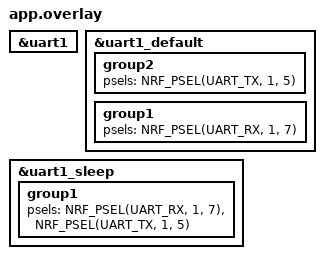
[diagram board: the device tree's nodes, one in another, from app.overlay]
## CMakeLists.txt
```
#
# Copyright (c) 2018 Nordic Semiconductor
#
# SPDX-License-Identifier: LicenseRef-Nordic-5-Clause
#
cmake_minimum_required(VERSION 3.20.0)

find_package(Zephyr REQUIRED HINTS $ENV{ZEPHYR_BASE})
project(ble_gateway)

# NORDIC SDK APP START
target_sources(app PRIVATE
  src/main.c
)
# NORDIC SDK APP END

zephyr_library_include_directories(${CMAKE_CURRENT_SOURCE_DIR})
```

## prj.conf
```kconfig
#
# Copyright (c) 2018 Nordic Semiconductor
#
# SPDX-License-Identifier: LicenseRef-Nordic-5-Clause
#

# Enable the UART driver
CONFIG_UART_ASYNC_API=y
CONFIG_SERIAL=y
CONFIG_CONSOLE=y
CONFIG_UART_CONSOLE=y

# Enable the BLE stack with GATT Client configuration
CONFIG_BT=y
CONFIG_BT_CENTRAL=y
CONFIG_BT_SMP=y
CONFIG_BT_GATT_CLIENT=y

# Enable the BLE modules from NCS
CONFIG_BT_NUS_CLIENT=y
CONFIG_BT_SCAN=y
CONFIG_BT_SCAN_FILTER_ENABLE=y
CONFIG_BT_SCAN_UUID_CNT=1
CONFIG_BT_GATT_DM=y
CONFIG_HEAP_MEM_POOL_SIZE=2048

# This example requires more stack
CONFIG_SYSTEM_WORKQUEUE_STACK_SIZE=2048
CONFIG_MAIN_STACK_SIZE=1536

# Enable bonding
CONFIG_BT_SETTINGS=y
CONFIG_FLASH=y
CONFIG_FLASH_PAGE_LAYOUT=y
CONFIG_FLASH_MAP=y
CONFIG_NVS=y
CONFIG_SETTINGS=y

# Config logger
CONFIG_LOG=y
CONFIG_USE_SEGGER_RTT=y
CONFIG_LOG_BACKEND_RTT=y
CONFIG_LOG_BACKEND_UART=n
CONFIG_LOG_PRINTK=n

CONFIG_ASSERT=y
```

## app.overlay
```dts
&uart1{
    status = "okay";
};
&uart1_default {
    group2 {
        psels = <NRF_PSEL(UART_TX, 1, 5)>;
    };

    group1 {
        psels = <NRF_PSEL(UART_RX, 1, 7)>;
    };
};

&uart1_sleep {
    group1 {
        psels = <NRF_PSEL(UART_RX, 1, 7)>, <NRF_PSEL(UART_TX, 1, 5)>;
    };
};
```

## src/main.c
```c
/*
 * Copyright (c) 2018 Nordic Semiconductor ASA
 *
 * SPDX-License-Identifier: LicenseRef-Nordic-5-Clause
 */

/** @file
 *  @brief Nordic UART Service Client sample
 */

#include <errno.h>
#include <zephyr/kernel.h>
#include <zephyr/device.h>
#include <zephyr/devicetree.h>
#include <zephyr/sys/byteorder.h>
#include <zephyr/sys/printk.h>

#include <zephyr/bluetooth/bluetooth.h>
#include <zephyr/bluetooth/hci.h>
#include <zephyr/bluetooth/conn.h>
#include <zephyr/bluetooth/uuid.h>
#include <zephyr/bluetooth/gatt.h>

#include <bluetooth/services/nus.h>
#include <bluetooth/services/nus_client.h>
#include <bluetooth/gatt_dm.h>
#include <bluetooth/scan.h>

#include <zephyr/settings/settings.h>

#include <zephyr/drivers/uart.h>

#include <zephyr/logging/log.h>

#include "gatt_chars.h"

#define LOG_MODULE_NAME central_uart
LOG_MODULE_REGISTER(LOG_MODULE_NAME);

/* UART payload buffer element size. */
#define UART_BUF_SIZE 20

#define KEY_PASSKEY_ACCEPT DK_BTN1_MSK
#define KEY_PASSKEY_REJECT DK_BTN2_MSK

#define NUS_WRITE_TIMEOUT K_MSEC(150)
#define UART_WAIT_FOR_BUF_DELAY K_MSEC(50)
#define UART_RX_TIMEOUT 50000 /* Wait for RX complete event time in microseconds. 500ms = 50000 */

static const struct device *uart = DEVICE_DT_GET(DT_NODELABEL(uart1));
static struct k_work_delayable uart_work;

K_SEM_DEFINE(nus_write_sem, 0, 1);

struct uart_data_t {
	void *fifo_reserved;
	uint8_t  data[UART_BUF_SIZE];
	uint16_t len;
};

static K_FIFO_DEFINE(fifo_uart_tx_data);
static K_FIFO_DEFINE(fifo_uart_rx_data);

struct bt_bot_client {

        /** Connection object. */
	struct bt_conn *conn;

        /** Internal state. */
	int voltage;
	int rpm;
	uint8_t last_move;

        /** GATT subscribe parameters for BOT voltage & RPM Characteristic. */
	struct bt_gatt_subscribe_params volt_notif_params;
	struct bt_gatt_subscribe_params rpm_notif_params;

        /** GATT write parameters for BOT Move & RPM Characteristic. */
	struct bt_gatt_write_params move_write_params;
	struct bt_gatt_write_params rpm_write_params;
};

static struct bt_conn *default_conn;
static struct bt_bot_client nus_client;

static void ble_data_sent(struct bt_bot_client *nus, uint8_t err,
					const uint8_t *const data, uint16_t len)
{
	ARG_UNUSED(nus);

	k_sem_give(&nus_write_sem);

	if (err) {
		printk("ATT error code: 0x%02X", err);
	}
}

static uint8_t ble_data_received(struct bt_bot_client *nus,
						const uint8_t *data, uint16_t len)
{
	ARG_UNUSED(nus);

	int err;

	for (uint16_t pos = 0; pos != len;) {
		struct uart_data_t *tx = k_malloc(sizeof(*tx));

		if (!tx) {
			printk("Not able to allocate UART send data buffer");
			return BT_GATT_ITER_CONTINUE;
		}

		/* Keep the last byte of TX buffer for potential LF char. */
		size_t tx_data_size = sizeof(tx->data) - 1;

		if ((len - pos) > tx_data_size) {
			tx->len = tx_data_size;
		} else {
			tx->len = (len - pos);
		}

		memcpy(tx->data, &data[pos], tx->len);

		pos += tx->len;

		/* Append the LF character when the CR character triggered
		 * transmission from the peer.
		 */
		if ((pos == len) && (data[len - 1] == '\r')) {
			tx->data[tx->len] = '\n';
			tx->len++;
		}

		err = uart_tx(uart, tx->data, tx->len, SYS_FOREVER_MS);
		if (err) {
			k_fifo_put(&fifo_uart_tx_data, tx);
		}
	}

	return BT_GATT_ITER_CONTINUE;
}

static void uart_cb(const struct device *dev, struct uart_event *evt, void *user_data)
{
	ARG_UNUSED(dev);

	static size_t aborted_len;
	struct uart_data_t *buf;
	static uint8_t *aborted_buf;
	static bool disable_req;
	switch (evt->type) {
	case UART_TX_DONE:
		LOG_DBG("UART_TX_DONE");
		if ((evt->data.tx.len == 0) ||
		    (!evt->data.tx.buf)) {
			printk("TX");
			return;
		}

		if (aborted_buf) {
			buf = CONTAINER_OF(aborted_buf, struct uart_data_t,
					   data[0]);
			aborted_buf = NULL;
			aborted_len = 0;
		} else {
			buf = CONTAINER_OF(evt->data.tx.buf,
					   struct uart_data_t,
					   data[0]);
		}

		k_free(buf);

		buf = k_fifo_get(&fifo_uart_tx_data, K_NO_WAIT);
		if (!buf) {
			return;
		}

		if (uart_tx(uart, buf->data, buf->len, SYS_FOREVER_MS)) {
			printk("Failed to send data over UART");
		}

		break;

	case UART_RX_RDY:
		LOG_DBG("UART_RX_RDY");
		buf = CONTAINER_OF(evt->data.rx.buf, struct uart_data_t, data[0]);
		buf->len += evt->data.rx.len;
		if (disable_req) {
			printk("disabled rx true");
			return;
		}
		if ((evt->data.rx.buf[buf->len - 1] == '\n') ||
		    (evt->data.rx.buf[buf->len - 1] == '\r')) {
			disable_req = true;
			uart_rx_disable(uart);
		}

		break;

	case UART_RX_DISABLED:
		LOG_DBG("UART_RX_DISABLED");
		disable_req = false;
		buf = k_malloc(sizeof(*buf));
		if (buf) {
			buf->len = 0;
		} else {
			printk("Not able to allocate UART receive buffer");
			k_work_reschedule(&uart_work, UART_WAIT_FOR_BUF_DELAY);
			return;
		}

		uart_rx_enable(uart, buf->data, sizeof(buf->data),
			       UART_RX_TIMEOUT);

		break;

	case UART_RX_BUF_REQUEST:
		LOG_DBG("UART_RX_BUF_REQUEST");
		buf = k_malloc(sizeof(*buf));
		if (buf) {
			buf->len = 0;
			uart_rx_buf_rsp(uart, buf->data, sizeof(buf->data));
		} else {
			printk("Not able to allocate UART receive buffer");
		}

		break;

	case UART_RX_BUF_RELEASED:
		LOG_DBG("UART_RX_BUF_RELEASED");
		buf = CONTAINER_OF(evt->data.rx_buf.buf, struct uart_data_t,
				   data[0]);
		if (buf->len > 0) {
			k_fifo_put(&fifo_uart_rx_data, buf);
		} else {
			k_free(buf);
		}

		break;

	case UART_TX_ABORTED:
		LOG_DBG("UART_TX_ABORTED");
		if (!aborted_buf) {
			aborted_buf = (uint8_t *)evt->data.tx.buf;
		}

		aborted_len += evt->data.tx.len;
		buf = CONTAINER_OF(aborted_buf, struct uart_data_t,
				   data[0]);

		uart_tx(uart, &buf->data[aborted_len],
			buf->len - aborted_len, SYS_FOREVER_MS);

		break;

	default:
		break;
	}
}

static void uart_work_handler(struct k_work *item)
{
	struct uart_data_t *buf;

	buf = k_malloc(sizeof(*buf));
	if (buf) {
		buf->len = 0;
	} else {
		printk("Not able to allocate UART receive buffer");
		k_work_reschedule(&uart_work, UART_WAIT_FOR_BUF_DELAY);
		return;
	}

	uart_rx_enable(uart, buf->data, sizeof(buf->data), UART_RX_TIMEOUT);
}

static int uart_init(void)
{
	int err;
	struct uart_data_t *rx;

	if (!device_is_ready(uart)) {
		printk("UART device not ready");
		return -ENODEV;
	}

	rx = k_malloc(sizeof(*rx));
	if (rx) {
		rx->len = 0;
	} else {
		return -ENOMEM;
	}

	k_work_init_delayable(&uart_work, uart_work_handler);
	err = uart_callback_set(uart, uart_cb, NULL);
	if (err) {
		return err;
	}

	return uart_rx_enable(uart, rx->data, sizeof(rx->data),
			      UART_RX_TIMEOUT);
}

static void discovery_complete(struct bt_gatt_dm *dm,
			       void *context)
{
	struct bt_bot_client *nus = context;
	printk("Service discovery completed");

	bt_gatt_dm_data_print(dm);

	bt_nus_handles_assign(dm, nus);
	
	bt_gatt_dm_data_release(dm);
}

static void discovery_service_not_found(struct bt_conn *conn,
					void *context)
{
	printk("Service not found");
}

static void discovery_error(struct bt_conn *conn,
			    int err,
			    void *context)
{
	printk("Error while discovering GATT database: (%d)", err);
}

struct bt_gatt_dm_cb discovery_cb = {
	.completed         = discovery_complete,
	.service_not_found = discovery_service_not_found,
	.error_found       = discovery_error,
};

static void gatt_discover(struct bt_conn *conn)
{
	int err;

	if (conn != default_conn) {
		return;
	}

	err = bt_gatt_dm_start(conn,
			       BT_UUID_BOT,
			       &discovery_cb,
			       &nus_client);
	if (err) {
		printk("could not start the discovery procedure, error "
			"code: %d", err);
	}
}

static void exchange_func(struct bt_conn *conn, uint8_t err, struct bt_gatt_exchange_params *params)
{
	if (!err) {
		printk("MTU exchange done");
	} else {
		printk("MTU exchange failed (err %" PRIu8 ")", err);
	}
}

static void connected(struct bt_conn *conn, uint8_t conn_err)
{
	char addr[BT_ADDR_LE_STR_LEN];
	int err;

	bt_addr_le_to_str(bt_conn_get_dst(conn), addr, sizeof(addr));

	if (conn_err) {
		printk("Failed to connect to %s (%d)", addr, conn_err);

		if (default_conn == conn) {
			bt_conn_unref(default_conn);
			default_conn = NULL;

			err = bt_scan_start(BT_SCAN_TYPE_SCAN_ACTIVE);
			if (err) {
				printk("Scanning failed to start (err %d)",
					err);
			}
		}

		return;
	}
	
	bt_addr_le_t address;
	bt_addr_le_from_str("F6:5E:C0:22:C7:AC","random",&address);
	if (bt_addr_le_eq(bt_conn_get_dst(conn), &address)) {
		printk("Connected to peripheral: %s", addr);
	} else {
		bt_conn_disconnect(conn, BT_ATT_ERR_AUTHENTICATION);
		printk("Wrong MAC - connection aborted");
		return;
	}

	static struct bt_gatt_exchange_params exchange_params;

	exchange_params.func = exchange_func;
	err = bt_gatt_exchange_mtu(conn, &exchange_params);
	if (err) {
		printk("MTU exchange failed (err %d)", err);
	}

	err = bt_conn_set_security(conn, BT_SECURITY_L3);
	if (err) {
		printk("Failed to set security: %d", err);

		gatt_discover(conn);
	}

	err = bt_scan_stop();
	if ((!err) && (err != -EALREADY)) {
		printk("Stop LE scan failed (err %d)", err);
	}
}

static void disconnected(struct bt_conn *conn, uint8_t reason)
{
	char addr[BT_ADDR_LE_STR_LEN];
	int err;

	bt_addr_le_to_str(bt_conn_get_dst(conn), addr, sizeof(addr));

	printk("Disconnected: %s (reason %u)", addr, reason);

	if (default_conn != conn) {
		return;
	}

	bt_conn_unref(default_conn);
	default_conn = NULL;

	err = bt_scan_start(BT_SCAN_TYPE_SCAN_ACTIVE);
	if (err) {
		printk("Scanning failed to start (err %d)",
			err);
	}
}

static void security_changed(struct bt_conn *conn, bt_security_t level,
			     enum bt_security_err err)
{
	char addr[BT_ADDR_LE_STR_LEN];

	bt_addr_le_to_str(bt_conn_get_dst(conn), addr, sizeof(addr));

	if (!err) {
		printk("Security changed: %s level %u", addr, level);
	} else {
		printk("Security failed: %s level %u err %d", addr,
			level, err);
	}

	gatt_discover(conn);
}

BT_CONN_CB_DEFINE(conn_callbacks) = {
	.connected = connected,
	.disconnected = disconnected,
	.security_changed = security_changed
};

static void scan_filter_match(struct bt_scan_device_info *device_info,
			      struct bt_scan_filter_match *filter_match,
			      bool connectable)
{
	char addr[BT_ADDR_LE_STR_LEN];

	bt_addr_le_to_str(device_info->recv_info->addr, addr, sizeof(addr));

	printk("Filters matched. Address: %s connectable: %d",
		addr, connectable);
}

static void scan_connecting_error(struct bt_scan_device_info *device_info)
{
	printk("Connecting failed");
}

static void scan_connecting(struct bt_scan_device_info *device_info,
			    struct bt_conn *conn)
{
	default_conn = bt_conn_ref(conn);
}

static int nus_client_init(void)
{
	int err;
	struct bt_nus_client_init_param init = {
		.cb = {
			.received = ble_data_received,
			.sent = ble_data_sent,
		}
	};

	err = bt_nus_client_init(&nus_client, &init);
	if (err) {
		printk("NUS Client initialization failed (err %d)", err);
		return err;
	}

	printk("NUS Client module initialized");
	return err;
}

BT_SCAN_CB_INIT(scan_cb, scan_filter_match, NULL,
		scan_connecting_error, scan_connecting);

static int scan_init(void)
{
	int err;
	struct bt_scan_init_param scan_init = {
		.connect_if_match = 1,
	};

	bt_scan_init(&scan_init);
	bt_scan_cb_register(&scan_cb);

	err = bt_scan_filter_add(BT_SCAN_FILTER_TYPE_UUID, BT_UUID_BOT);
	if (err) {
		printk("Scanning filters cannot be set (err %d)", err);
		return err;
	}

	err = bt_scan_filter_enable(BT_SCAN_UUID_FILTER, false);
	if (err) {
		printk("Filters cannot be turned on (err %d)", err);
		return err;
	}

	printk("Scan module initialized");
	return err;
}


static void auth_cancel(struct bt_conn *conn)
{
	char addr[BT_ADDR_LE_STR_LEN];

	bt_addr_le_to_str(bt_conn_get_dst(conn), addr, sizeof(addr));

	printk("Pairing cancelled: %s", addr);
}


static void pairing_complete(struct bt_conn *conn, bool bonded)
{
	char addr[BT_ADDR_LE_STR_LEN];

	bt_addr_le_to_str(bt_conn_get_dst(conn), addr, sizeof(addr));

	printk("Pairing completed: %s, bonded: %d", addr, bonded);
}


static void pairing_failed(struct bt_conn *conn, enum bt_security_err reason)
{
	char addr[BT_ADDR_LE_STR_LEN];

	bt_addr_le_to_str(bt_conn_get_dst(conn), addr, sizeof(addr));

	printk("Pairing failed conn: %s, reason %d", addr, reason);
}

static struct bt_conn_auth_cb conn_auth_callbacks = {
	.cancel = auth_cancel,
};

static struct bt_conn_auth_info_cb conn_auth_info_callbacks = {
	.pairing_complete = pairing_complete,
	.pairing_failed = pairing_failed
};

int main(void)
{
	int err;

	err = bt_conn_auth_cb_register(&conn_auth_callbacks);
	if (err) {
		printk("Failed to register authorization callbacks.");
		return 0;
	}

	err = bt_conn_auth_info_cb_register(&conn_auth_info_callbacks);
	if (err) {
		printk("Failed to register authorization info callbacks.\n");
		return 0;
	}

	err = bt_enable(NULL);
	if (err) {
		printk("Bluetooth init failed (err %d)", err);
		return 0;
	}
	printk("Bluetooth initialized");

	if (IS_ENABLED(CONFIG_SETTINGS)) {
		settings_load();
	}

	err = uart_init();
	if (err != 0) {
		printk("uart_init failed (err %d)", err);
		return 0;
	}

	err = scan_init();
	if (err != 0) {
		printk("scan_init failed (err %d)", err);
		return 0;
	}

	err = nus_client_init();
	if (err != 0) {
		printk("nus_client_init failed (err %d)", err);
		return 0;
	}

	printk("Starting Bluetooth Central UART example\n");

	err = bt_scan_start(BT_SCAN_TYPE_SCAN_ACTIVE);
	if (err) {
		printk("Scanning failed to start (err %d)", err);
		return 0;
	}

	printk("Scanning successfully started");

	for (;;) {
		/* Wait indefinitely for data to be sent over Bluetooth */
		struct uart_data_t *buf = k_fifo_get(&fifo_uart_rx_data,
						     K_FOREVER);
		err = bt_nus_client_send(&nus_client, buf->data, buf->len);
		
		if (err) {
			printk("Failed to send data over BLE connection"
				"(err %d)", err);
		}

		err = k_sem_take(&nus_write_sem, NUS_WRITE_TIMEOUT);
		if (err) {
			printk("NUS send timeout");
		}

		k_free(buf);
	}
}
```

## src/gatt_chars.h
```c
/*
 * Copyright (c) 2018 Nordic Semiconductor ASA
 *
 * SPDX-License-Identifier: LicenseRef-Nordic-5-Clause
 */

#ifndef BT_LBS_H_
#define BT_FREEBOT_H_

/**@file
 * @defgroup bt_lbs LED Button Service API
 * @{
 * @brief API for the LED Button Service (LBS).
 */

#ifdef __cplusplus
extern "C" {
#endif

#include <zephyr/types.h>

//95429c1a-6c94-4957-bf09-40889fbe50ed
#define BT_UUID_BOT_VAL \
	BT_UUID_128_ENCODE(0x95429c1a, 0x4957, 0xefde, 0xbf09, 0x40889fbe50ed)

/** @brief Voltage Characteristic UUID. 
 * Notify
 * Read
*/
#define BT_UUID_BOT_VOLT_VAL \
	BT_UUID_128_ENCODE(0x95429c1b, 0x4957, 0xefde, 0xbf09, 0x40889fbe50ed)
/** @brief RPM Read Characteristic UUID. 
 * Notify
 * Read
*/
#define BT_UUID_BOT_RPM_READ_VAL \
	BT_UUID_128_ENCODE(0x95429c1c, 0x4957, 0xefde, 0xbf09, 0x40889fbe50ed)
/** @brief RPM Write Characteristic UUID. 
 * Write
*/
#define BT_UUID_BOT_RPM_WRITE_VAL \
	BT_UUID_128_ENCODE(0x95429c1d, 0x4957, 0xefde, 0xbf09, 0x40889fbe50ed)
/** @brief MOVE Characteristic UUID. 
 * Write
*/
#define BT_UUID_BOT_MOVE_VAL \
	BT_UUID_128_ENCODE(0x95429c1e, 0x4957, 0xefde, 0xbf09, 0x40889fbe50ed)

#define BT_UUID_BOT             BT_UUID_DECLARE_128(BT_UUID_BOT_VAL)
#define BT_UUID_BOT_VOLT        BT_UUID_DECLARE_128(BT_UUID_BOT_VOLT_VAL)
#define BT_UUID_BOT_RPM_READ    BT_UUID_DECLARE_128(BT_UUID_BOT_RPM_READ_VAL)
#define BT_UUID_BOT_RPM_WRITE   BT_UUID_DECLARE_128(BT_UUID_BOT_RPM_WRITE_VAL)
#define BT_UUID_BOT_MOVE	    BT_UUID_DECLARE_128(BT_UUID_BOT_MOVE_VAL)


/** @brief Callback type for when rpm & movement is changed & called */
typedef void (*rpm_write_cb_t)(const int rpm);
typedef void (*move_cb_t)(const uint8_t move);

typedef int (*volt_cb_t)(void);
typedef int (*rpm_read_cb_t)(void);

/** @brief Callback struct used by the LBS Service. */
struct freebot_svc_cb {
    rpm_write_cb_t rpm_write_cb;
	rpm_read_cb_t rpm_read_cb;
    move_cb_t move_cb;
	volt_cb_t volt_cb;
};

/** @brief Initialize the Service.
 *
 * This function registers application callback functions with the * Service
 *
 * @param[in] callbacks Struct containing pointers to callback functions
 *			used by the service. This pointer can be NULL
 *			if no callback functions are defined.
 *
 *
 * @retval 0 If the operation was successful.
 *           Otherwise, a (negative) error code is returned.
 */
int freebot_svc_init(struct freebot_svc_cb *callbacks);

int freebot_send_rpm_notify(int rpm);
int freebot_send_volt_notify(int voltage);

#ifdef __cplusplus
}
#endif

/**
 * @}
 */

#endif /* BT_LBS_H_ */
```
